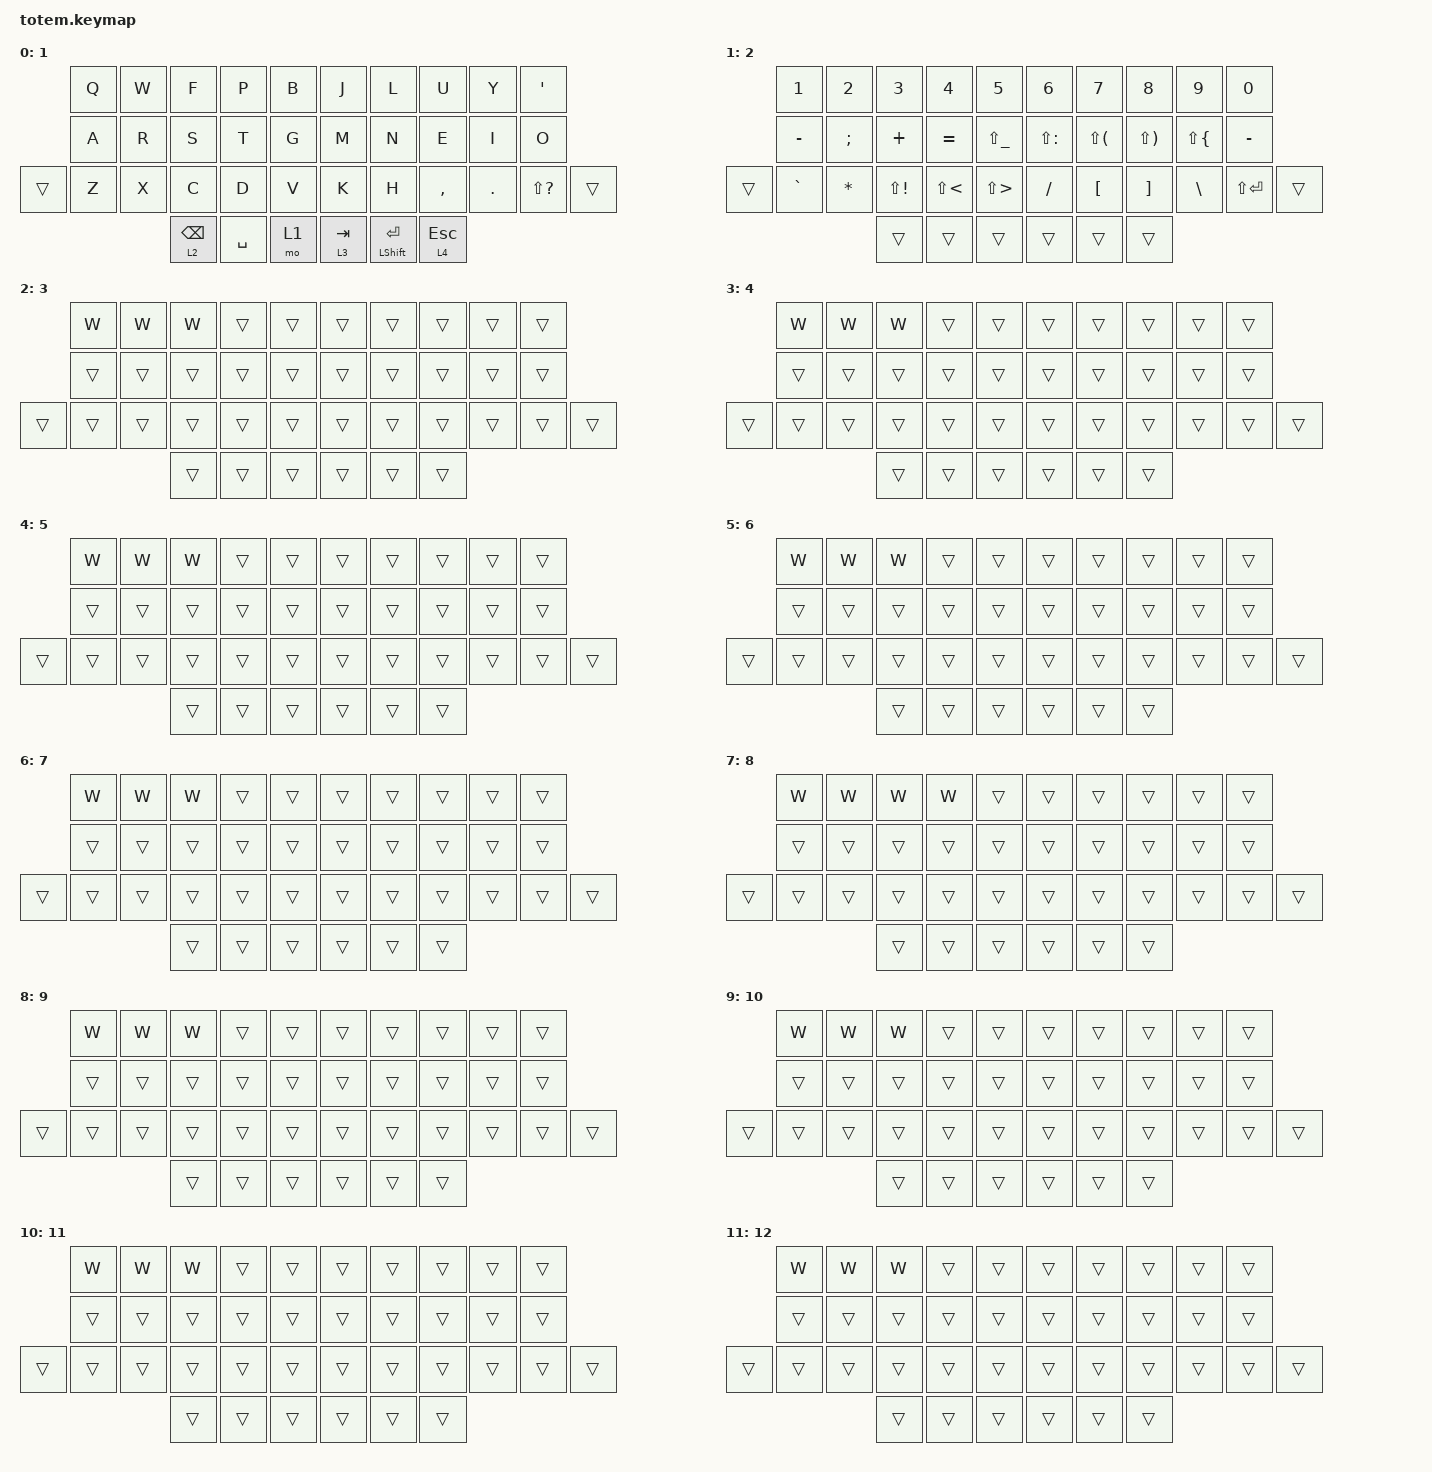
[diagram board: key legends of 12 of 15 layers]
//
//                                                        ▀▀▀▀▀     ▀▀▀▀▀          ▀▀█▀▀
//                                                        ▄▀▀▀▄  ▄  ▄▀▀▀▄  ▄  ▄▀▀▀▄  █  ▄▀▀▀▄
//                                                        █   █  █  █   █  █  █   █  █  █   █
//                                                         ▀▀▀   █   ▀▀▀   █   ▀▀▀   ▀   ▀▀▀
//                                                               █      ▄▄▄█▄▄▄    █   █  
//                                                               ▀      █  █  █     █▄█
//                                                             ▀▀▀▀▀    █  █  █      ▀
//                                                                      ▀  ▀  ▀
//
// ▄▄▄▄▄▄▄▄▄▄▄▄▄▄▄▄▄▄▄▄▄▄▄▄▄▄▄▄▄▄▄▄▄▄▄▄▄▄▄▄▄▄▄▄▄▄▄▄▄▄▄▄▄▄▄▄▄▄▄▄▄▄▄▄▄▄▄▄▄▄▄▄▄▄▄▄▄▄▄▄▄▄▄▄▄▄▄▄▄▄▄▄▄▄▄▄▄▄▄▄▄▄▄▄▄▄▄▄▄▄▄▄▄▄▄▄▄▄▄▄▄▄▄▄▄▄▄▄▄▄▄▄▄▄▄▄▄▄▄▄▄▄▄▄▄▄▄▄▄

#include <behaviors.dtsi>
#include <dt-bindings/zmk/bt.h>
#include <dt-bindings/zmk/keys.h>

/ {
    keymap {
        compatible = "zmk,keymap";

        Main {
            bindings = <
        &kp Q  &kp W  &kp F            &kp P      &kp B  &kp J      &kp L                 &kp U         &kp Y    &kp SQT
        &kp A  &kp R  &kp S            &kp T      &kp G  &kp M      &kp N                 &kp E         &kp I    &kp O
&trans  &kp Z  &kp X  &kp C            &kp D      &kp V  &kp K      &kp H                 &kp COMMA     &kp DOT  &kp LS(QMARK)  &trans
                      &lt 2 BACKSPACE  &kp SPACE  &mo 1  &lt 3 TAB  &mt LEFT_SHIFT ENTER  &lt 4 ESCAPE
            >;

            label = "1";
        };

        Secondary {
            bindings = <
        &kp N1     &kp N2    &kp N3        &kp N4      &kp N5         &kp N6         &kp N7        &kp N8        &kp N9        &kp N0
        &kp MINUS  &kp SEMI  &kp PLUS      &kp EQUAL   &kp LS(UNDER)  &kp LS(COLON)  &kp LS(LPAR)  &kp LS(RPAR)  &kp LS(LBRC)  &kp MINUS
&trans  &kp GRAVE  &kp STAR  &kp LS(EXCL)  &kp LS(LT)  &kp LS(GT)     &kp FSLH       &kp LBKT      &kp RBKT      &kp BSLH      &kp LS(RET)  &trans
                             &trans        &trans      &trans         &trans         &trans        &trans
            >;

            label = "2";
        };

        Functions {
            bindings = <
        &kp W   &kp W   &kp W   &trans  &trans  &trans  &trans  &trans  &trans  &trans
        &trans  &trans  &trans  &trans  &trans  &trans  &trans  &trans  &trans  &trans
&trans  &trans  &trans  &trans  &trans  &trans  &trans  &trans  &trans  &trans  &trans  &trans
                        &trans  &trans  &trans  &trans  &trans  &trans
            >;

            label = "3";
        };

        layer_3 {
            bindings = <
        &kp W   &kp W   &kp W   &trans  &trans  &trans  &trans  &trans  &trans  &trans
        &trans  &trans  &trans  &trans  &trans  &trans  &trans  &trans  &trans  &trans
&trans  &trans  &trans  &trans  &trans  &trans  &trans  &trans  &trans  &trans  &trans  &trans
                        &trans  &trans  &trans  &trans  &trans  &trans
            >;

            label = "4";
        };

        layer_4 {
            bindings = <
        &kp W   &kp W   &kp W   &trans  &trans  &trans  &trans  &trans  &trans  &trans
        &trans  &trans  &trans  &trans  &trans  &trans  &trans  &trans  &trans  &trans
&trans  &trans  &trans  &trans  &trans  &trans  &trans  &trans  &trans  &trans  &trans  &trans
                        &trans  &trans  &trans  &trans  &trans  &trans
            >;

            label = "5";
        };

        layer_5 {
            bindings = <
        &kp W   &kp W   &kp W   &trans  &trans  &trans  &trans  &trans  &trans  &trans
        &trans  &trans  &trans  &trans  &trans  &trans  &trans  &trans  &trans  &trans
&trans  &trans  &trans  &trans  &trans  &trans  &trans  &trans  &trans  &trans  &trans  &trans
                        &trans  &trans  &trans  &trans  &trans  &trans
            >;

            label = "6";
        };

        layer_6 {
            bindings = <
        &kp W   &kp W   &kp W   &trans  &trans  &trans  &trans  &trans  &trans  &trans
        &trans  &trans  &trans  &trans  &trans  &trans  &trans  &trans  &trans  &trans
&trans  &trans  &trans  &trans  &trans  &trans  &trans  &trans  &trans  &trans  &trans  &trans
                        &trans  &trans  &trans  &trans  &trans  &trans
            >;

            label = "7";
        };

        layer_7 {
            bindings = <
        &kp W   &kp W   &kp W   &kp W   &trans  &trans  &trans  &trans  &trans  &trans
        &trans  &trans  &trans  &trans  &trans  &trans  &trans  &trans  &trans  &trans
&trans  &trans  &trans  &trans  &trans  &trans  &trans  &trans  &trans  &trans  &trans  &trans
                        &trans  &trans  &trans  &trans  &trans  &trans
            >;

            label = "8";
        };

        layer_8 {
            bindings = <
        &kp W   &kp W   &kp W   &trans  &trans  &trans  &trans  &trans  &trans  &trans
        &trans  &trans  &trans  &trans  &trans  &trans  &trans  &trans  &trans  &trans
&trans  &trans  &trans  &trans  &trans  &trans  &trans  &trans  &trans  &trans  &trans  &trans
                        &trans  &trans  &trans  &trans  &trans  &trans
            >;

            label = "9";
        };

        layer_9 {
            bindings = <
        &kp W   &kp W   &kp W   &trans  &trans  &trans  &trans  &trans  &trans  &trans
        &trans  &trans  &trans  &trans  &trans  &trans  &trans  &trans  &trans  &trans
&trans  &trans  &trans  &trans  &trans  &trans  &trans  &trans  &trans  &trans  &trans  &trans
                        &trans  &trans  &trans  &trans  &trans  &trans
            >;

            label = "10";
        };

        layer_10 {
            bindings = <
        &kp W   &kp W   &kp W   &trans  &trans  &trans  &trans  &trans  &trans  &trans
        &trans  &trans  &trans  &trans  &trans  &trans  &trans  &trans  &trans  &trans
&trans  &trans  &trans  &trans  &trans  &trans  &trans  &trans  &trans  &trans  &trans  &trans
                        &trans  &trans  &trans  &trans  &trans  &trans
            >;

            label = "11";
        };

        layer_11 {
            bindings = <
        &kp W   &kp W   &kp W   &trans  &trans  &trans  &trans  &trans  &trans  &trans
        &trans  &trans  &trans  &trans  &trans  &trans  &trans  &trans  &trans  &trans
&trans  &trans  &trans  &trans  &trans  &trans  &trans  &trans  &trans  &trans  &trans  &trans
                        &trans  &trans  &trans  &trans  &trans  &trans
            >;

            label = "12";
        };

        layer_12 {
            bindings = <
        &kp W   &kp W   &kp W   &trans  &trans  &trans  &trans  &trans  &trans  &trans
        &trans  &trans  &trans  &trans  &trans  &trans  &trans  &trans  &trans  &trans
&trans  &trans  &trans  &trans  &trans  &trans  &trans  &trans  &trans  &trans  &trans  &trans
                        &trans  &trans  &trans  &trans  &trans  &trans
            >;

            label = "13";
        };

        layer_13 {
            bindings = <
        &kp W   &kp W   &kp W   &trans  &trans  &trans  &trans  &trans  &trans  &trans
        &trans  &trans  &trans  &trans  &trans  &trans  &trans  &trans  &trans  &trans
&trans  &trans  &trans  &trans  &trans  &trans  &trans  &trans  &trans  &trans  &trans  &trans
                        &trans  &trans  &trans  &trans  &trans  &trans
            >;

            label = "14";
        };

        ToTeMs {
            bindings = <
        &bt BT_PRV  &bt BT_NXT  &bt BT_CLR  &trans  &trans  &trans  &trans  &trans  &trans  &trans
        &trans      &trans      &trans      &trans  &trans  &trans  &trans  &trans  &trans  &trans
&trans  &trans      &trans      &trans      &trans  &trans  &trans  &trans  &trans  &trans  &trans  &trans
                                &trans      &trans  &trans  &trans  &trans  &trans
            >;

            label = "15";
        };
    };
};
